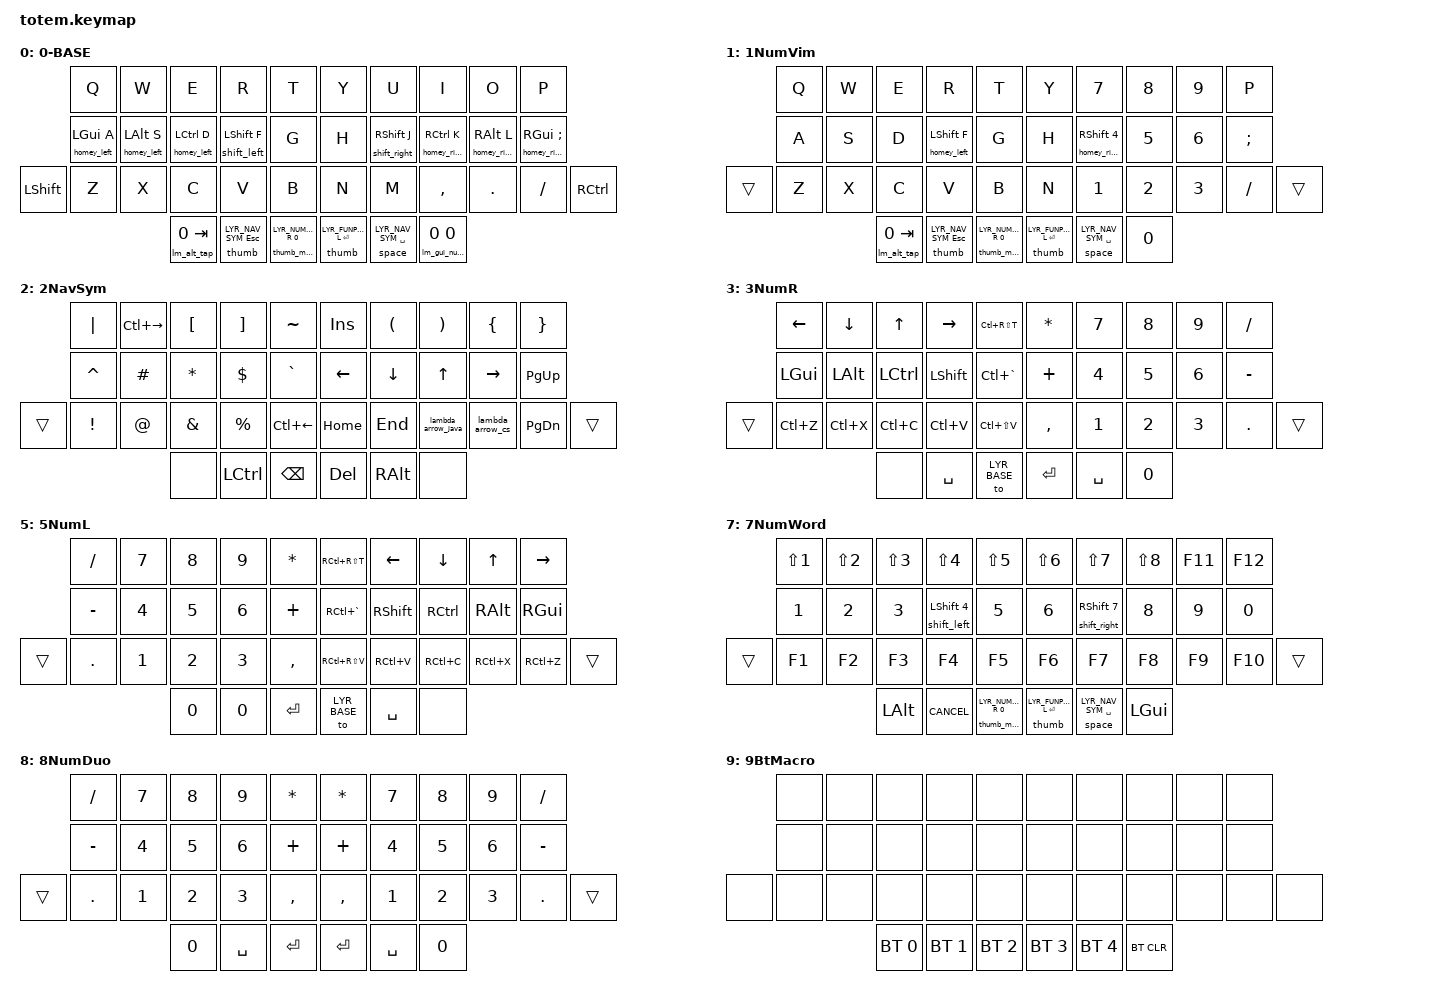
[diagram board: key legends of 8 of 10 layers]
//
//                                                        ▀▀▀▀▀     ▀▀▀▀▀          ▀▀█▀▀
//                                                        ▄▀▀▀▄  ▄  ▄▀▀▀▄  ▄  ▄▀▀▀▄  █  ▄▀▀▀▄
//                                                        █   █  █  █   █  █  █   █  █  █   █
//                                                         ▀▀▀   █   ▀▀▀   █   ▀▀▀   ▀   ▀▀▀
//                                                               █      ▄▄▄█▄▄▄    █   █  
//                                                               ▀      █  █  █     █▄█
//                                                             ▀▀▀▀▀    █  █  █      ▀
//                                                                      ▀  ▀  ▀
//
// ▄▄▄▄▄▄▄▄▄▄▄▄▄▄▄▄▄▄▄▄▄▄▄▄▄▄▄▄▄▄▄▄▄▄▄▄▄▄▄▄▄▄▄▄▄▄▄▄▄▄▄▄▄▄▄▄▄▄▄▄▄▄▄▄▄▄▄▄▄▄▄▄▄▄▄▄▄▄▄▄▄▄▄▄▄▄▄▄▄▄▄▄▄▄▄▄▄▄▄▄▄▄▄▄▄▄▄▄▄▄▄▄▄▄▄▄▄▄▄▄▄▄▄▄▄▄▄▄▄▄▄▄▄▄▄▄▄▄▄▄▄▄▄▄▄▄▄▄▄

#include "keypos_38keys.h"
#include <behaviors.dtsi>
#include <dt-bindings/zmk/bt.h>
#include <dt-bindings/zmk/keys.h>
#include <dt-bindings/zmk/outputs.h>

/* Enable keymap features that require forks */
//#define HAS_MOUSE_KEYS

#define LYR_BASE 0
#define LYR_NUM_VIM 1
#define LYR_NAV_SYM 2
#define LYR_NUMPAD_R 3
#define LYR_FUNPAD_L 4
#define LYR_NUMPAD_L 5
#define LYR_SC_WIN 6
#define LYR_NUM_WORD 7
#define LYR_NUMPAD_DUO 8
#define LYR_BT_MACRO 9

#define KEYS_L LT0 LT1 LT2 LT3 LT4 LM0 LM1 LM2 LM3 LM4 LB0 LB1 LB2 LB3 LB4 LB5
#define KEYS_R RT0 RT1 RT2 RT3 RT4 RM0 RM1 RM2 RM3 RM4 RB0 RB1 RB2 RB3 RB4 RB5
#define KEYS_T LH2 LH1 LH0 RH0 RH1 RH2

#include "includes/settings.dtsi"
#include "includes/macros.dtsi"
#include "includes/behaviors_hrm_sunaku.dtsi"
#include "includes/behaviors_custom_caps_word.dtsi"
#include "includes/behaviors_thumb_specials.dtsi"
#include "includes/combos.dtsi"

/ {
    keymap {
        compatible = "zmk,keymap";

        BASE {
            display-name = "0-BASE";
            bindings = <
        // ╭────────────────────────┬────────────────────────┬────────────────────────┬────────────────────────┬────────────────────────╮    ╭────────────────────────┬────────────────────────┬────────────────────────┬────────────────────────┬────────────────────────╮
            &kp Q                    &kp W                    &kp E                    &kp R                    &kp T                         &kp Y                    &kp U                    &kp I                    &kp O                    &kp P
        // ├────────────────────────┼────────────────────────┼────────────────────────┼────────────────────────┼────────────────────────┤    ├────────────────────────┼────────────────────────┼────────────────────────┼────────────────────────┼────────────────────────┤
            &homey_left LGUI A       &homey_left LALT S       &homey_left LCTRL D      &shift_left LSHFT F      &kp G                         &kp H                    &shift_right RSHIFT J    &homey_right RCTRL K     &homey_right RALT L      &homey_right RGUI SEMI
        // ├────────────────────────┼────────────────────────┼────────────────────────┼────────────────────────┼────────────────────────┤    ├────────────────────────┼────────────────────────┼────────────────────────┼────────────────────────┼────────────────────────┤
&kp LSHFT   &kp Z                    &kp X                    &kp C                    &kp V                    &kp B                         &kp N                    &kp M                    &kp COMMA                &kp DOT                  &kp SLASH                 &kp RCTRL
        // ╰────────────────────────┴────────────────────────┼────────────────────────┼────────────────────────┼────────────────────────┤    ├────────────────────────┼────────────────────────┼────────────────────────┼────────────────────────┴────────────────────────╯
                                                              &lm_alt_tap 0 TAB    &thumb LYR_NAV_SYM ESC   &thumb_mo_capsword LYR_NUMPAD_R 0 &thumb LYR_FUNPAD_L RET  &space LYR_NAV_SYM SPACE &lm_gui_numvim 0 0
        //                                                   ╰────────────────────────┴────────────────────────┴────────────────────────╯    ╰────────────────────────┴────────────────────────┴────────────────────────╯
            >;
        };

        NUM_VIM {
            display-name = "1NumVim";
            bindings = <
        // ╭────────────────────────┬────────────────────────┬────────────────────────┬────────────────────────┬────────────────────────╮    ╭────────────────────────┬────────────────────────┬────────────────────────┬────────────────────────┬────────────────────────╮
            &kp Q                    &kp W                    &kp E                    &kp R                    &kp T                         &kp Y                    &kp N7                   &kp N8                   &kp N9                   &kp P
        // ├────────────────────────┼────────────────────────┼────────────────────────┼────────────────────────┼────────────────────────┤    ├────────────────────────┼────────────────────────┼────────────────────────┼────────────────────────┼────────────────────────┤
            &kp A                    &kp S                    &kp D                    &homey_left LSHFT F      &kp G                         &kp H                    &homey_right RSHIFT N4   &kp N5                   &kp N6                   &kp SEMI
        // ├────────────────────────┼────────────────────────┼────────────────────────┼────────────────────────┼────────────────────────┤    ├────────────────────────┼────────────────────────┼────────────────────────┼────────────────────────┼────────────────────────┤
&trans      &kp Z                    &kp X                    &kp C                    &kp V                    &kp B                         &kp N                    &kp N1                   &kp N2                   &kp N3                   &kp SLASH                 &trans
        // ╰────────────────────────┴────────────────────────┼────────────────────────┼────────────────────────┼────────────────────────┤    ├────────────────────────┼────────────────────────┼────────────────────────┼────────────────────────┴────────────────────────╯
                                                              &lm_alt_tap 0 TAB    &thumb LYR_NAV_SYM ESC   &thumb_mo_capsword LYR_NUMPAD_R 0 &thumb LYR_FUNPAD_L RET  &space LYR_NAV_SYM SPACE &kp N0
        //                                                   ╰────────────────────────┴────────────────────────┴────────────────────────╯    ╰────────────────────────┴────────────────────────┴────────────────────────╯
            >;
        };

        NAV_SYM {
            display-name = "2NavSym";
            bindings = <
        // ╭────────────────────────┬────────────────────────┬────────────────────────┬────────────────────────┬────────────────────────╮    ╭────────────────────────┬────────────────────────┬────────────────────────┬────────────────────────┬────────────────────────╮
            &kp PIPE                 &kp LC(RIGHT)            &kp LEFT_BRACKET         &kp RIGHT_BRACKET        &kp TILDE                     &kp INSERT               &kp LEFT_PARENTHESIS     &kp RIGHT_PARENTHESIS    &kp LEFT_BRACE           &kp RIGHT_BRACE
        // ├────────────────────────┼────────────────────────┼────────────────────────┼────────────────────────┼────────────────────────┤    ├────────────────────────┼────────────────────────┼────────────────────────┼────────────────────────┼────────────────────────┤
            &kp CARET                &kp POUND                &kp STAR                 &kp DOLLAR               &kp GRAVE                     &kp LEFT                 &kp DOWN                 &kp UP                   &kp RIGHT                &kp PAGE_UP
        // ├────────────────────────┼────────────────────────┼────────────────────────┼────────────────────────┼────────────────────────┤    ├────────────────────────┼────────────────────────┼────────────────────────┼────────────────────────┼────────────────────────┤
&trans      &kp EXCL                 &kp AT                   &kp AMPS                 &kp PERCENT              &kp LC(LEFT)                  &kp HOME                 &kp END                  &lambda_arrow_java       &lambda_arrow_cs         &kp PAGE_DOWN             &trans
        // ╰────────────────────────┴────────────────────────┼────────────────────────┼────────────────────────┼────────────────────────┤    ├────────────────────────┼────────────────────────┼────────────────────────┼────────────────────────┴────────────────────────╯
                                                              &none                    &kp LCTRL                &kp BACKSPACE                 &kp DELETE               &kp RALT                 &none
        //                                                   ╰────────────────────────┴────────────────────────┴────────────────────────╯    ╰────────────────────────┴────────────────────────┴────────────────────────╯
            >;
        };

        NUMPAD_R {
            display-name = "3NumR";
            bindings = <
        // ╭────────────────────────┬────────────────────────┬────────────────────────┬────────────────────────┬────────────────────────╮    ╭────────────────────────┬────────────────────────┬────────────────────────┬────────────────────────┬────────────────────────╮
            &kp LEFT                 &kp DOWN                 &kp UP                   &kp RIGHT                &kp LC(RS(T))                 &kp ASTERISK             &kp N7                   &kp N8                   &kp N9                   &kp SLASH
        // ├────────────────────────┼────────────────────────┼────────────────────────┼────────────────────────┼────────────────────────┤    ├────────────────────────┼────────────────────────┼────────────────────────┼────────────────────────┼────────────────────────┤
            &kp LGUI                 &kp LALT                 &kp LCTRL                &kp LSHFT                &kp LC(GRAVE)                 &kp PLUS                 &kp N4                   &kp N5                   &kp N6                   &kp MINUS
        // ├────────────────────────┼────────────────────────┼────────────────────────┼────────────────────────┼────────────────────────┤    ├────────────────────────┼────────────────────────┼────────────────────────┼────────────────────────┼────────────────────────┤
&trans      &kp LC(Z)                &kp LC(X)                &kp LC(C)                &kp LC(V)                &kp LC(LS(V))                 &kp COMMA                &kp N1                   &kp N2                   &kp N3                   &kp DOT                   &trans
        // ╰────────────────────────┴────────────────────────┼────────────────────────┼────────────────────────┼────────────────────────┤    ├────────────────────────┼────────────────────────┼────────────────────────┼────────────────────────┴────────────────────────╯
                                                              &none                    &kp SPACE                &to LYR_BASE                  &kp ENTER                &kp SPACE                &kp N0
        //                                                   ╰────────────────────────┴────────────────────────┴────────────────────────╯    ╰────────────────────────┴────────────────────────┴────────────────────────╯
            >;
        };

        FUNPAD_L {
            display-name = "4FunL";
            bindings = <
        // ╭────────────────────────┬────────────────────────┬────────────────────────┬────────────────────────┬────────────────────────╮    ╭────────────────────────┬────────────────────────┬────────────────────────┬────────────────────────┬────────────────────────╮
            &kp F9                   &kp F10                  &kp F11                  &kp F12                  &kp ASTERISK                  &kp RC(RS(T))            &kp LEFT                 &kp DOWN                 &kp UP                   &kp RIGHT
        // ├────────────────────────┼────────────────────────┼────────────────────────┼────────────────────────┼────────────────────────┤    ├────────────────────────┼────────────────────────┼────────────────────────┼────────────────────────┼────────────────────────┤
            &kp F5                   &kp F6                   &kp F7                   &kp F8                   &kp PLUS                      &kp RC(G)                &kp RSHFT                &kp RCTRL                &kp RALT                 &kp RGUI
        // ├────────────────────────┼────────────────────────┼────────────────────────┼────────────────────────┼────────────────────────┤    ├────────────────────────┼────────────────────────┼────────────────────────┼────────────────────────┼────────────────────────┤
            &kp F1                   &kp F2                   &kp F3                   &kp F4                   &kp COMMA                     &kp RC(RS(V))            &kp RC(V)                &kp RC(C)                &kp RC(X)                &kp RC(Z)                 &trans
        // ╰────────────────────────┴────────────────────────┼────────────────────────┼────────────────────────┼────────────────────────┤    ├────────────────────────┼────────────────────────┼────────────────────────┼────────────────────────┴────────────────────────╯
                                                              &none                    &kp ESC                  &kp ENTER                     &to LYR_BASE             &kp SPACE                &none
        //                                                   ╰────────────────────────┴────────────────────────┴────────────────────────╯    ╰────────────────────────┴────────────────────────┴────────────────────────╯
            >;
        };

        NUMPAD_L {
            display-name = "5NumL";
            bindings = <
        // ╭────────────────────────┬────────────────────────┬────────────────────────┬────────────────────────┬────────────────────────╮    ╭────────────────────────┬────────────────────────┬────────────────────────┬────────────────────────┬────────────────────────╮
            &kp SLASH                &kp N7                   &kp N8                   &kp N9                   &kp ASTERISK                  &kp RC(RS(T))            &kp LEFT                 &kp DOWN                 &kp UP                   &kp RIGHT
        // ├────────────────────────┼────────────────────────┼────────────────────────┼────────────────────────┼────────────────────────┤    ├────────────────────────┼────────────────────────┼────────────────────────┼────────────────────────┼────────────────────────┤
            &kp MINUS                &kp N4                   &kp N5                   &kp N6                   &kp PLUS                      &kp RC(GRAVE)            &kp RSHFT                &kp RCTRL                &kp RALT                 &kp RGUI
        // ├────────────────────────┼────────────────────────┼────────────────────────┼────────────────────────┼────────────────────────┤    ├────────────────────────┼────────────────────────┼────────────────────────┼────────────────────────┼────────────────────────┤
&trans      &kp DOT                  &kp N1                   &kp N2                   &kp N3                   &kp COMMA                     &kp RC(RS(V))            &kp RC(V)                &kp RC(C)                &kp RC(X)                &kp RC(Z)                 &trans
        // ╰────────────────────────┴────────────────────────┼────────────────────────┼────────────────────────┼────────────────────────┤    ├────────────────────────┼────────────────────────┼────────────────────────┼────────────────────────┴────────────────────────╯
                                                              &kp N0                   &kp N0                   &kp ENTER                     &to LYR_BASE             &kp SPACE                &none
        //                                                   ╰────────────────────────┴────────────────────────┴────────────────────────╯    ╰────────────────────────┴────────────────────────┴────────────────────────╯
            >;
        };

        SC_WIN {
            display-name = "6ScWin";
            bindings = <
        // ╭────────────────────────┬────────────────────────┬────────────────────────┬────────────────────────┬────────────────────────╮    ╭────────────────────────┬────────────────────────┬────────────────────────┬────────────────────────┬────────────────────────╮
            &none                    &kp LS(DOWN)             &kp UP                   &kp LS(UP)               &kp LC(T)                     &kp LC(T)                &kp LS(UP)               &kp UP                   &kp LS(DOWN)             &none 
        // ├────────────────────────┼────────────────────────┼────────────────────────┼────────────────────────┼────────────────────────┤    ├────────────────────────┼────────────────────────┼────────────────────────┼────────────────────────┼────────────────────────┤
            &kp LC(LEFT)             &kp LEFT                 &kp DOWN                 &kp RIGHT                &kp LC(RIGHT)                 &kp LC(LEFT)             &kp LEFT                 &kp DOWN                 &kp RIGHT                &kp LC(RIGHT)
        // ├────────────────────────┼────────────────────────┼────────────────────────┼────────────────────────┼────────────────────────┤    ├────────────────────────┼────────────────────────┼────────────────────────┼────────────────────────┼────────────────────────┤
            &kp LS(S)                &kp LS(LEFT)             &kp HOME                 &kp LS(RIGHT)            &kp LS(T)                     &kp LS(T)                &kp LS(LEFT)             &kp HOME                 &kp LS(RIGHT)            &kp LS(S)                 &trans
        // ╰────────────────────────┴────────────────────────┼────────────────────────┼────────────────────────┼────────────────────────┤    ├────────────────────────┼────────────────────────┼────────────────────────┼────────────────────────┴────────────────────────╯
                                                              &none                    &none                    &none                         &none                    &none                    &none
        //                                                   ╰────────────────────────┴────────────────────────┴────────────────────────╯    ╰────────────────────────┴────────────────────────┴────────────────────────╯
            >;
        };

        NUM_WORD {
            display-name = "7NumWord";
            bindings = <
        // ╭────────────────────────┬────────────────────────┬────────────────────────┬────────────────────────┬────────────────────────╮    ╭────────────────────────┬────────────────────────┬────────────────────────┬────────────────────────┬────────────────────────╮
            &kp LS(N1)               &kp LS(N2)               &kp LS(N3)               &kp LS(N4)               &kp LS(N5)                    &kp LS(N6)               &kp LS(N7)               &kp LS(N8)               &kp F11                  &kp F12
        // ├────────────────────────┼────────────────────────┼────────────────────────┼────────────────────────┼────────────────────────┤    ├────────────────────────┼────────────────────────┼────────────────────────┼────────────────────────┼────────────────────────┤
            &kp N1                   &kp N2                   &kp N3                   &shift_left LSHIFT N4    &kp N5                        &kp N6                   &shift_right RSHFT N7    &kp N8                   &kp N9                   &kp N0
        // ├────────────────────────┼────────────────────────┼────────────────────────┼────────────────────────┼────────────────────────┤    ├────────────────────────┼────────────────────────┼────────────────────────┼────────────────────────┼────────────────────────┤
&trans      &kp F1                   &kp F2                   &kp F3                   &kp F4                   &kp F5                        &kp F6                   &kp F7                   &kp F8                   &kp F9                   &kp F10                   &trans
        // ╰────────────────────────┴────────────────────────┼────────────────────────┼────────────────────────┼────────────────────────┤    ├────────────────────────┼────────────────────────┼────────────────────────┼────────────────────────┴────────────────────────╯
                                                              &kp LALT                 &kp K_CANCEL         &thumb_mo_capsword LYR_NUMPAD_R 0 &thumb LYR_FUNPAD_L RET  &space LYR_NAV_SYM SPACE &kp LGUI
        //                                                   ╰────────────────────────┴────────────────────────┴────────────────────────╯    ╰────────────────────────┴────────────────────────┴────────────────────────╯
            >;
        };

        NUMPAD_DUO {
            display-name = "8NumDuo";
            bindings = <
        // ╭────────────────────────┬────────────────────────┬────────────────────────┬────────────────────────┬────────────────────────╮    ╭────────────────────────┬────────────────────────┬────────────────────────┬────────────────────────┬────────────────────────╮
            &kp SLASH                &kp N7                   &kp N8                   &kp N9                   &kp ASTERISK                  &kp ASTERISK             &kp N7                   &kp N8                   &kp N9                   &kp SLASH
        // ├────────────────────────┼────────────────────────┼────────────────────────┼────────────────────────┼────────────────────────┤    ├────────────────────────┼────────────────────────┼────────────────────────┼────────────────────────┼────────────────────────┤
            &kp MINUS                &kp N4                   &kp N5                   &kp N6                   &kp PLUS                      &kp PLUS                 &kp N4                   &kp N5                   &kp N6                   &kp MINUS
        // ├────────────────────────┼────────────────────────┼────────────────────────┼────────────────────────┼────────────────────────┤    ├────────────────────────┼────────────────────────┼────────────────────────┼────────────────────────┼────────────────────────┤
&trans      &kp DOT                  &kp N1                   &kp N2                   &kp N3                   &kp COMMA                     &kp COMMA                &kp N1                   &kp N2                   &kp N3                   &kp DOT                   &trans
        // ╰────────────────────────┴────────────────────────┼────────────────────────┼────────────────────────┼────────────────────────┤    ├────────────────────────┼────────────────────────┼────────────────────────┼────────────────────────┴────────────────────────╯
                                                              &kp N0                   &kp SPACE                &kp ENTER                     &kp ENTER                &kp SPACE                &kp N0
        //                                                   ╰────────────────────────┴────────────────────────┴────────────────────────╯    ╰────────────────────────┴────────────────────────┴────────────────────────╯
            >;
        };

        BT_MACRO {
            display-name = "9BtMacro";
            bindings = <
        // ╭────────────────────────┬────────────────────────┬────────────────────────┬────────────────────────┬────────────────────────╮    ╭────────────────────────┬────────────────────────┬────────────────────────┬────────────────────────┬────────────────────────╮
            &none                    &none                    &none                    &none                    &none                         &none                    &none                    &none                    &none                    &none
        // ├────────────────────────┼────────────────────────┼────────────────────────┼────────────────────────┼────────────────────────┤    ├────────────────────────┼────────────────────────┼────────────────────────┼────────────────────────┼────────────────────────┤
            &none                    &none                    &none                    &none                    &none                         &none                    &none                    &none                    &none                    &none
        // ├────────────────────────┼────────────────────────┼────────────────────────┼────────────────────────┼────────────────────────┤    ├────────────────────────┼────────────────────────┼────────────────────────┼────────────────────────┼────────────────────────┤
&none       &none                    &none                    &none                    &none                    &none                         &none                    &none                    &none                    &none                    &none                     &none
        // ╰────────────────────────┴────────────────────────┼────────────────────────┼────────────────────────┼────────────────────────┤    ├────────────────────────┼────────────────────────┼────────────────────────┼────────────────────────┴────────────────────────╯
                                                              &bt BT_SEL 0             &bt BT_SEL 1             &bt BT_SEL 2                  &bt BT_SEL 3             &bt BT_SEL 4             &bt BT_CLR
        //                                                   ╰────────────────────────┴────────────────────────┴────────────────────────╯    ╰────────────────────────┴────────────────────────┴────────────────────────╯
            >;
        };
    };
};
